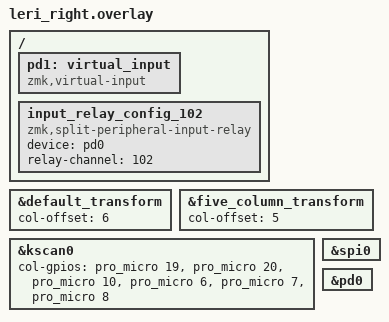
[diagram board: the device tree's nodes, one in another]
/*
 * Copyright (c) 2020 ZMK Contributors
 *
 * SPDX-License-Identifier: MIT
 */
 
#include "leri.dtsi"

&default_transform {
	col-offset = <6>;
};

&five_column_transform {
	col-offset = <5>;
};

&kscan0 {
	col-gpios
		= <&pro_micro 19 (GPIO_ACTIVE_HIGH | GPIO_PULL_DOWN)>
		, <&pro_micro 20 (GPIO_ACTIVE_HIGH | GPIO_PULL_DOWN)>
		, <&pro_micro 10 (GPIO_ACTIVE_HIGH | GPIO_PULL_DOWN)>
		, <&pro_micro 6 (GPIO_ACTIVE_HIGH | GPIO_PULL_DOWN)>
		, <&pro_micro 7 (GPIO_ACTIVE_HIGH | GPIO_PULL_DOWN)>
		, <&pro_micro 8 (GPIO_ACTIVE_HIGH | GPIO_PULL_DOWN)>
		;
};

&spi0 {
	status = "okay";
};

/* enable &pd0 on split peripheral. typical input device for zephyr input subsystem. */
/* NOTE 1: use the same device alias (&pd0) on central and peripheral(s) is alright. */
/* NOTE 2: input event shall be intecepted by module `zmk-split-peripheral-input-relay`. */

/* this is an alias of your actual wired input device sensor in your peripheral shield. */
/* e.g. SPI optical sensor for trackball */
&pd0 {
	status = "okay";
	/* the rest of sensor config should be config here, e.g. gpios */
};

/ {
	/* THIS make keymap binding happy only, nothing happen on peripheral side */
	pd1: virtual_input {
		compatible = "zmk,virtual-input";
	};

	/* for peripheral side, define (input-device)-to-(relay-channel) mapping */
	input_relay_config_102 {
		compatible = "zmk,split-peripheral-input-relay";

		/* peripheral side input device, used to... */
		/*  - be intecepted on peripheral; */
		/*  - and then, be resurrected as `zmk,virtual-device` on central; */
		device = <&pd0>;
		
		/* channel id, used to be be transfered along with all input events. */
		/* NOTE 1: pick any 8bit integer. (1 - 255) */
		/* NOTE 2: should matching relay-channel on central overlay */
		relay-channel = <102>;
	};
};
